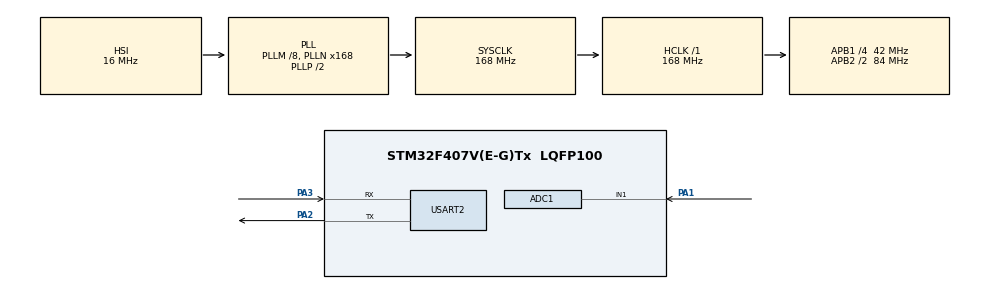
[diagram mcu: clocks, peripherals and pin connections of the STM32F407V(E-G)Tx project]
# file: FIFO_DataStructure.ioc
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ADC1.Channel-5\#ChannelRegularConversion=ADC_CHANNEL_1
ADC1.ContinuousConvMode=DISABLE
ADC1.NbrOfConversionFlag=1
ADC1.Rank-5\#ChannelRegularConversion=1
ADC1.SamplingTime-5\#ChannelRegularConversion=ADC_SAMPLETIME_3CYCLES
ADC1.master=1
Mcu.Family=STM32F4
Mcu.Name=STM32F407V(E-G)Tx
Mcu.Package=LQFP100
NVIC.ADC_IRQn=true\:0\:0\:false\:false\:true\:true\:true\:true
NVIC.PriorityGroup=NVIC_PRIORITYGROUP_0
PA1.Signal=ADCx_IN1
PA2.Mode=Asynchronous
PA2.Signal=USART2_TX
PA3.Mode=Asynchronous
PA3.Signal=USART2_RX
PH0-OSC_IN.Mode=HSE-External-Oscillator
PH0-OSC_IN.Signal=RCC_OSC_IN
PH1-OSC_OUT.Mode=HSE-External-Oscillator
PH1-OSC_OUT.Signal=RCC_OSC_OUT
ProjectManager.HeapSize=0x200
ProjectManager.StackSize=0x400
ProjectManager.TargetToolchain=STM32CubeIDE
RCC.48MHZClocksFreq_Value=48000000
RCC.AHBFreq_Value=168000000
RCC.APB1CLKDivider=RCC_HCLK_DIV4
RCC.APB1Freq_Value=42000000
RCC.APB1TimFreq_Value=84000000
RCC.APB2CLKDivider=RCC_HCLK_DIV2
RCC.APB2Freq_Value=84000000
RCC.APB2TimFreq_Value=168000000
RCC.CortexFreq_Value=168000000
RCC.HCLKFreq_Value=168000000
RCC.HSE_VALUE=8000000
RCC.HSI_VALUE=16000000
RCC.LSE_VALUE=32768
RCC.PLLM=8
RCC.PLLN=168
RCC.PLLQ=7
RCC.SYSCLKFreq_VALUE=168000000
RCC.SYSCLKSource=RCC_SYSCLKSOURCE_PLLCLK
RCC.VCOOutputFreq_Value=336000000
SH.ADCx_IN1.0=ADC1_IN1,IN1
USART2.VirtualMode=VM_ASYNC
board=STM32F407G-DISC1

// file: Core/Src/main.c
/* USER CODE BEGIN Header */
/**
  ******************************************************************************
  * @file           : main.c
  * @brief          : Main program body
  ******************************************************************************
  * @attention
  *
  * Copyright (c) 2026 STMicroelectronics.
  * All rights reserved.
  *
  * This software is licensed under terms that can be found in the LICENSE file
  * in the root directory of this software component.
  * If no LICENSE file comes with this software, it is provided AS-IS.
  *
  ******************************************************************************
  */
/* USER CODE END Header */
#include "main.h"
#include "adc.h"
#include "usart.h"
#include "gpio.h"

/* USER CODE BEGIN Includes */
//#include "stm32f407xx.h"
#include "signals.h"
#include "stdio.h"
#include "arm_math.h"
#include <math.h>
#include "stdlib.h"
#define moving_avg_pts 11
#include "fifo.h"
#include "string.h"
/* USER CODE END Includes */

void SystemClock_Config(void);

/* USER CODE BEGIN 0 */
volatile uint8_t  flag = 0;
uint32_t sample_count = 0;
volatile uint32_t fifo_overflow_count = 0;   /* FIFO was full when a sample arrived */
volatile uint32_t adc_timeout_count   = 0;   /* ADC didn't finish converting in time */

rx_DataType val = 0;
rx_DataType rx_data;

/* USER CODE BEGIN PTD */
#define adc_buff_len 500
rx_DataType adc_buff[adc_buff_len];   /* same type as the FIFO holds */
/* USER CODE END PTD */
uint32_t adc_ready = 0;
void HAL_SYSTICK_Callback(void)
{
	if(!adc_ready)
	{
		return;
	}
    if (HAL_ADC_Start(&hadc1) != HAL_OK)
    {
        return;
    }

    if (HAL_ADC_PollForConversion(&hadc1, 1) == HAL_OK)
    {
        val = (rx_DataType)HAL_ADC_GetValue(&hadc1);

        if (rx_fifo_put(val) == RXFIFO_Done)
        {
            sample_count++;
            if (sample_count >= adc_buff_len)
            {
                flag = 1;
                sample_count = 0;
            }
        }
        else
        {
            fifo_overflow_count++;   /* main loop is draining too slowly */
        }
    }
    else
    {
        adc_timeout_count++;         /* diagnostic only — should stay 0 */
    }
}
/* USER CODE END 0 */

int main(void)
{

  /* MCU Configuration--------------------------------------------------------*/

  /* Reset of all peripherals, Initializes the Flash interface and the Systick. */
  HAL_Init();

  /* Configure the system clock */
  SystemClock_Config();

  /* Initialize all configured peripherals */
  MX_GPIO_Init();
  MX_USART2_UART_Init();
  MX_ADC1_Init();
  adc_ready = 1;

  /* USER CODE BEGIN 2 */

//  moving_avg(inputSignal_f32_1kHz_15kHz, inputSignal_f32_1kHz_15kHz_out, sig2_len, moving_avg_pts);
//  plot_signal( inputSignal_f32_1kHz_15kHz_out,sig2_len );
  /* USER CODE END 2 */

  /* Infinite loop */
  /* USER CODE BEGIN WHILE */

  /*Initializing fifo*/
  rx_fifo_init();
  char bf[50];
  while (1)
  {
    /* USER CODE END WHILE */

    /* USER CODE BEGIN 3 */
	  if (flag == 1)
	      {
	          int received = 0;

	          for (int i = 0; i < adc_buff_len; i++)
	          {
	              if (rx_fifo_get(&rx_data) == RXFIFO_Done)
	              {
	                  adc_buff[i] = rx_data;
	                  received++;
	              }
	              else
	              {
	                  break;
	              }
	          }

	          for (int i = 0; i < received; i++)
	          {
	              sprintf(bf, "%d\r\n", adc_buff[i]);
	              HAL_UART_Transmit(&huart2, (uint8_t *)bf, strlen(bf), HAL_MAX_DELAY);
	          }

	          flag = 0;
	      }
	    }
  /* USER CODE END 3 */
}

void SystemClock_Config(void)
{
  RCC_OscInitTypeDef RCC_OscInitStruct = {0};
  RCC_ClkInitTypeDef RCC_ClkInitStruct = {0};

  /** Configure the main internal regulator output voltage
  */
  __HAL_RCC_PWR_CLK_ENABLE();
  __HAL_PWR_VOLTAGESCALING_CONFIG(PWR_REGULATOR_VOLTAGE_SCALE1);

  /** Initializes the RCC Oscillators according to the specified parameters
  * in the RCC_OscInitTypeDef structure.
  */
  RCC_OscInitStruct.OscillatorType = RCC_OSCILLATORTYPE_HSI;
  RCC_OscInitStruct.HSIState = RCC_HSI_ON;
  RCC_OscInitStruct.HSICalibrationValue = RCC_HSICALIBRATION_DEFAULT;
  RCC_OscInitStruct.PLL.PLLState = RCC_PLL_ON;
  RCC_OscInitStruct.PLL.PLLSource = RCC_PLLSOURCE_HSI;
  RCC_OscInitStruct.PLL.PLLM = 8;
  RCC_OscInitStruct.PLL.PLLN = 168;
  RCC_OscInitStruct.PLL.PLLP = RCC_PLLP_DIV2;
  RCC_OscInitStruct.PLL.PLLQ = 7;
  if (HAL_RCC_OscConfig(&RCC_OscInitStruct) != HAL_OK)
  {
    Error_Handler();
  }

  /** Initializes the CPU, AHB and APB buses clocks
  */
  RCC_ClkInitStruct.ClockType = RCC_CLOCKTYPE_HCLK|RCC_CLOCKTYPE_SYSCLK
                              |RCC_CLOCKTYPE_PCLK1|RCC_CLOCKTYPE_PCLK2;
  RCC_ClkInitStruct.SYSCLKSource = RCC_SYSCLKSOURCE_PLLCLK;
  RCC_ClkInitStruct.AHBCLKDivider = RCC_SYSCLK_DIV1;
  RCC_ClkInitStruct.APB1CLKDivider = RCC_HCLK_DIV4;
  RCC_ClkInitStruct.APB2CLKDivider = RCC_HCLK_DIV2;

  if (HAL_RCC_ClockConfig(&RCC_ClkInitStruct, FLASH_LATENCY_5) != HAL_OK)
  {
    Error_Handler();
  }
}

/* USER CODE BEGIN 4 */
void plot_signal(float32_t *arr,uint32_t sig_len)
{
	for(int i=0; i<sig_len; i++)
		    {
		        long val = (long)(arr[i] * 100000);
		        long int_part  = val / 100000;
		        long frac_part = labs(val % 100000);

		        if (val < 0 && int_part == 0) {
		            printf("-%ld.%05ld\r\n", int_part, frac_part);
		        } else {
		            printf("%ld.%05ld\r\n", int_part, frac_part);
		        }
		        HAL_Delay(50);
		    }

}

void moving_avg(float32_t* sig_src_arr, float32_t* sig_out_arr, uint32_t signal_len,
		       uint32_t filter_pts)
{
	for(int i = floor(filter_pts/2); i<(signal_len - (filter_pts/2))-1; i++)
	{
		sig_out_arr[i] = 0;
		for(int j = -(floor(filter_pts/2)); j<floor(filter_pts/2); j++)
		{
			sig_out_arr[i] = sig_out_arr[i] + sig_src_arr[i+j];
		}
		sig_out_arr[i] = sig_out_arr[i]/filter_pts;
	}
}

/* USER CODE END 4 */

void Error_Handler(void)
{
  __disable_irq();
  while (1)
  {
  }
}
